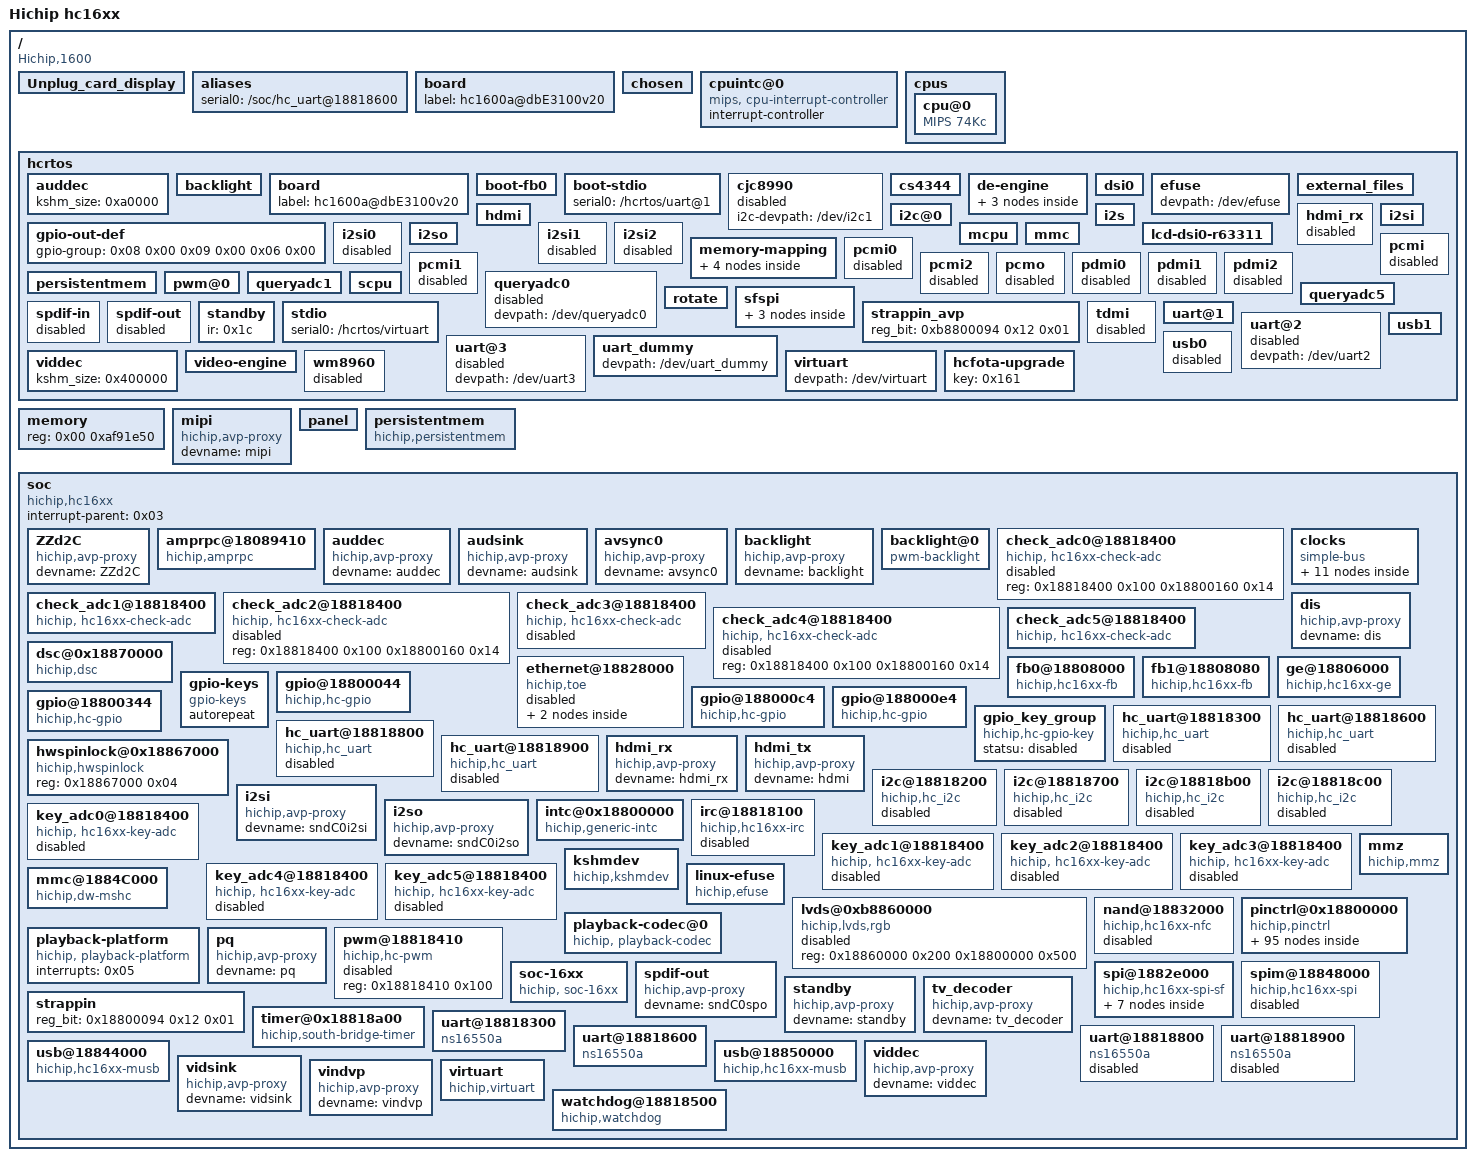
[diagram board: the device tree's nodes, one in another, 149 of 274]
/* r36sx-v26.dts — /hcrtos/ del NOR-DTB de FÁBRICA (fix-forward D-2b) */
#define CONFIG_MEMORY_SIZE 0x10000000
#define CONFIG_LINUX_MEMORY_SIZE 0xAF91E50
#define CONFIG_LINUX_MEMORY_OFFSET 0x0
#define CONFIG_FRAMEBUFFER_STATIC_PHYS (CONFIG_LINUX_MEMORY_OFFSET + CONFIG_LINUX_MEMORY_SIZE)
#define HCRTOS_SYSMEM_SIZE 0xB53600
#define HCRTOS_SYSMEM_OFFSET 0xBDA2E50
#define HCRTOS_BOOTMEM_SIZE 0x2000000
#define HCRTOS_BOOTMEM_OFFSET (((HCRTOS_SYSMEM_OFFSET < 0xc000000 ? HCRTOS_SYSMEM_OFFSET : 0xc000000) - HCRTOS_BOOTMEM_SIZE) & 0xffff0000)

/dts-v1/;

/ {
	#address-cells = <0x01>;
	#size-cells = <0x01>;
	compatible = "Hichip,1600";
	interrupt-parent = <0x01>;
	model = "Hichip hc16xx";

	Unplug_card_display {
		status = "okay";
	};

	aliases {
		serial0 = "/soc/hc_uart@18818600";
	};

	board {
		label = "hc1600a@dbE3100v20";
	};

	chosen {
		bootargs = "root=/dev/ram0 rootfstype=ramfs rw init=/linuxrc console=tty1 earlycon= no_console_suspend noirqdebug";
		stdout-path = "serial0:115200n8";
	};

	cpuintc@0 {
		#address-cells = <0x00>;
		#interrupt-cells = <0x01>;
		compatible = "mips, cpu-interrupt-controller";
		interrupt-controller;
		linux,phandle = <0x01>;
		phandle = <0x01>;
	};

	cpus {
		#address-cells = <0x01>;
		#size-cells = <0x00>;

		cpu@0 {
			clock = <0x05>;
			clocks = <0x02>;
			compatible = "MIPS 74Kc";
			device_type = "cpu";
			mcpu-dig-pll-clk = <0x384>;
			reg = <0x00>;
		};
	};

	hcrtos {
		#address-cells = <0x01>;
		#size-cells = <0x01>;

		auddec {
			kshm_size = <0xa0000>;
		};

		backlight {
			backlight-frequency = <0x186a0>;
			backlight-pwmdev = "/dev/pwm0";
			default-brightness-level = <0x99>;
			default-off;
			scale = <0xff>;
			status = "okay";
		};

		board {
			label = "hc1600a@dbE3100v20";
		};

		boot-fb0 {
			bits_per_pixel = <0x20>;
			buffer-header-size = <0x1000>;
			buffer-phy-static = <0xaf91e50 0xe11000>;
			buffer-source = "static";
			extra-buffer-size = <0x00>;
			reg = <0x1883a000 0x1000>;
			scale = <0x280 0x1e0 0x280 0x1e0>;
			status = "okay";
			use-static-header;
			xoffset = <0x00>;
			xres = <0x280>;
			xres_virtual = <0x280>;
			yoffset = <0x00>;
			yres = <0x1e0>;
			yres_virtual = <0x1e0>;
		};

		boot-stdio {
			serial0 = "/hcrtos/uart@1";
		};

		cjc8990 {
			i2c-devpath = "/dev/i2c1";
			status = "disabled";
		};

		cs4344 {
			status = "okay";
		};

		de-engine {
			cvbs-output = <0x00>;
			de-dig-pll-clk = <0x190>;
			de4k-clock = <0x06>;
			de4k-output = <0x01>;
			dual-output = <0x00>;
			mm-vc-fb-size = <0x19e000>;
			pinmux-vga-hsync = <0x0c 0x06>;
			pinmux-vga-vsync = <0x0d 0x06>;
			status = "okay";
			tvtype = <0x0f>;
			vga-output = <0x00>;
			vga-rgb-dac-b = <0x01>;
			vga-rgb-dac-g = <0x02>;
			vga-rgb-dac-r = <0x04>;

			VPInitInfo {

				rgb-cfg {
					b-rgb-enable = <0x01>;
					lcd-width = <0x280>;
					prgb-mode = <0x00>;
					rgb-mode = <0x00>;

					timing-para {
						active-polarity = <0x01>;
						b-enable = <0x01>;
						dpll-clock-reg-value = <0x00>;
						frame-rate = <0xea60>;
						h-active-len = <0x280>;
						h-back-len = <0x28>;
						h-display_len = <0x00>;
						h-front-len = <0xa8>;
						h-sync-len = <0x14>;
						h-sync-level = <0x00>;
						h-total-len = <0x364>;
						output-clock = <0x01>;
						v-active-len = <0x1e0>;
						v-back-len = <0x0c>;
						v-display_len = <0x00>;
						v-front-len = <0x16>;
						v-sync-len = <0x04>;
						v-sync-level = <0x00>;
						v-total-len = <0x206>;
					};
				};
			};
		};

		dsi0 {
			clock-frequency = <0x00>;
			dsi,cfg = <0x1c>;
			dsi,flags = <0x3fd>;
			dsi,format = <0x05>;
			dsi,lanes = <0x04>;
			dsi,swap = <0x00>;
			enable-delay-ms = <0x0a>;
			h-sync-level = <0x00>;
			init-delay-ms = <0x14>;
			lcd-reset-gpios-rtos = <0x06 0x01>;
			mipi-drive-strength = <0x02>;
			panel-init-sequence = <0x15c80211 0x156402 0x2900ff00 0x00 0x00 0x00 0x00 0x00 0x00 0x00 0x00 0x00 0x00 0x00 0x00 0x00 0x00 0x00 0x00 0x00 0x00 0x00 0x00 0x00 0x00 0x00 0x00 0x00 0x00 0x00 0x00 0x00 0x00 0x00 0x00 0x00 0x00 0x00 0x00 0x00 0x00 0x00 0x00 0x00 0x00 0x00 0x00 0x00 0x00 0x00 0x00 0x00 0x00 0x00 0x00 0x00 0x00 0x00 0x00 0x00 0x00 0x00 0x00 0x00 0x00 0x00 0x00 0x00 0x00 0x00 0x00 0x00 0x00 0x00 0x00 0x00 0x00 0x00 0x00 0x00 0x00 0x00 0x00 0x00 0x00 0x00 0x00 0x00 0x00 0x00 0x00 0x00 0x00 0x00 0x00 0x00 0x00 0x00 0x00 0x00 0x00 0x00 0x00 0x00 0x00 0x00 0x00 0x00 0x00 0x00 0x00 0x00 0x00 0x00 0x00 0x00 0x00 0x00 0x00 0x00 0x00 0x00 0x00 0x00 0x00 0x00 0x00 0x00 0x00 0x00 0x00 0x00 0x00 0x00 0x00 0x00 0x00 0x00 0x00 0x00 0x00 0x00 0x00 0x00 0x00 0x00 0x00 0x00 0x00 0x00 0x00 0x00 0x00 0x00 0x00 0x00 0x00 0x00 0x00 0x00 0x00 0x00 0x00 0x00 0x00 0x00 0x00 0x00 0x00 0x00 0x00 0x00 0x00 0x00 0x00 0x00 0x00 0x00 0x00 0x00 0x00 0x00 0x00 0x00 0x00 0x00 0x00 0x00 0x00 0x00 0x00 0x00 0x00 0x00 0x00 0x00 0x00 0x00 0x00 0x00 0x00 0x00 0x00 0x00 0x00 0x00 0x00 0x00 0x00 0x00 0x00 0x00 0x00 0x00 0x00 0x00 0x00 0x00 0x00 0x00 0x00 0x00 0x00 0x00 0x00 0x00 0x00 0x00 0x00 0x00 0x00 0x00 0x00 0x00 0x00 0x00 0x00 0x00 0x00 0x00 0x00 0x00 0x00 0x00 0x00 0x00 0x00 0x00 0x00 0x00 0x00 0x00 0x00 0x00 0x00 0x00 0x00 0x00 0x00 0x00 0x00 0x00 0x00 0x00 0x00 0x00 0x00 0x00 0x00 0x00 0x00 0x00 0x00 0x00 0x00 0x00 0x00 0x00 0x00 0x00 0x00 0x00 0x00 0x00 0x00 0x00 0x00 0x00 0x00 0x00 0x00 0x00 0x00 0x00 0x00 0x00 0x00 0x00 0x00 0x00 0x00 0x00 0x00 0x00 0x00 0x00 0x00 0x00 0x00 0x00 0x00 0x00 0x00 0x00 0x00 0x00 0x00 0x00 0x00 0x00 0x00 0x00 0x00 0x00 0x00 0x00 0x00 0x00 0x00 0x00 0x00 0x00 0x00 0x00 0x00 0x00 0x00 0x00 0x00 0x00 0x00 0x00 0x00 0x00 0x00 0x00 0x00 0x00 0x00 0x00 0x00 0x00 0x00 0x00 0x00 0x00 0x00 0x00 0x00 0x00 0x00 0x00 0x00 0x00 0x00 0x00 0x00 0x00 0x00 0x00 0x00 0x00 0x00 0x00 0x00 0x00 0x00 0x00 0x00 0x00 0x00 0x00 0x00 0x00 0x00 0x00 0x00 0x00 0x00 0x00 0x00 0x00 0x00 0x00 0x00 0x00 0x00 0x00 0x00 0x00 0x00 0x00 0x00 0x00 0x00 0x00 0x00 0x00 0x00 0x00 0x00 0x00 0x00 0x00 0x00 0x00 0x00 0x00 0x00 0x00 0x00 0x00 0x00 0x00 0x00 0x00 0x00 0x00 0x00 0x00 0x00 0x00 0x00 0x00 0x00 0x00 0x00 0x00 0x00 0x00 0x00 0x00 0x00 0x00 0x00 0x00 0x00 0x00 0x00 0x00 0x00 0x00 0x00 0x00 0x00 0x00 0x00 0x00 0x00 0x00 0x00 0x00 0x00 0x00 0x00 0x00 0x00 0x00 0x00 0x00 0x00 0x00 0x00 0x00 0x00 0x00 0x00 0x00 0x00 0x00 0x00 0x00 0x00 0x00 0x00 0x00 0x00 0x00 0x00 0x00 0x00 0x00 0x00 0x00 0x00 0x00 0x00 0x00 0x00 0x00 0x00 0x00 0x00 0x00 0x00 0x00 0x00 0x00 0x00 0x00 0x00 0x00 0x00 0x00 0x00 0x00 0x00 0x00 0x00 0x00 0x00 0x00 0x00 0x00 0x00 0x00 0x00 0x00 0x00 0x00 0x00 0x00 0x00 0x00 0x00 0x00 0x00 0x00 0x00 0x00 0x00 0x00 0x00 0x00 0x00 0x00 0x00 0x00 0x00 0x00 0x00 0x00 0x00 0x00 0x00 0x00 0x00 0x00 0x00 0x00 0x00 0x00 0x00 0x00 0x00 0x00 0x00 0x00 0x00 0x00 0x00 0x00 0x00 0x00 0x00 0x00 0x00 0x00 0x00 0x00 0x00 0x00 0x00 0x00 0x00 0x00 0x00 0x00 0x00 0x00 0x00 0x00 0x00 0x00 0x00 0x00 0x00 0x00 0x00 0x00 0x00 0x00 0x00 0x00 0x00 0x00 0x00 0x00 0x00 0x00 0x00 0x00 0x00 0x00 0x00 0x00 0x00 0x00 0x00 0x00 0x00 0x00 0x00 0x00 0x00 0x00 0x00 0x00 0x00 0x00 0x00 0x00 0x00 0x00 0x00 0x00 0x00 0x00 0x00 0x00 0x00 0x00 0x00 0x00 0x00 0x00 0x00 0x00 0x00 0x00 0x00 0x00 0x00 0x00 0x00 0x00 0x00 0x00 0x00 0x00 0x00 0x00 0x00 0x00 0x00 0x00 0x00 0x00 0x00 0x00 0x00 0x00 0x00 0x00 0x00 0x00 0x00 0x00 0x00 0x00 0x00 0x00 0x00 0x00 0x00 0x00 0x00 0x00 0x00 0x00 0x00 0x00 0x00 0x00 0x00 0x00 0x00 0x00 0x00 0x00>;
			prepare-delay-ms = <0x0a>;
			reg = <0x1884a000 0x300 0x18800444 0x08 0x18800080 0x08>;
			reset-delay-ms = <0x78>;
			src-sel = <0x01>;
			status = "okay";
			v-sync-level = <0x00>;
		};

		efuse {
			devpath = "/dev/efuse";
			status = "okay";
		};

		external_files {
			part-num = <0x04>;
			part1-filename = "dtb.bin";
			part1-label = "dtb";
			part2-filename = "avp.uImage";
			part2-label = "avp";
			part3-filename = "vmlinux.uImage";
			part3-label = "linux";
			part4-filename = "xgame-logo.bmp";
			part4-label = "logo";
			path-prefix = "boot";
		};

		gpio-out-def {
			gpio-group = <0x08 0x00 0x09 0x00 0x06 0x00>;
			status = "okay";
		};

		hdmi {
			default-off = <0x01>;
			i2c-devpath = "/dev/i2c0";
			pinmux-hotplug = <0x10 0x01>;
			status = "okay";
			tx_source = <0x01>;
		};

		hdmi_rx {
			pinmux-detect = <0x74 0x03>;
			pinmux-hotplugin = <0x74 0x00>;
			pinmux-i2c = <0x76 0x08 0x77 0x08>;
			status = "disabled";
		};

		i2c@0 {
			baudrate = <0x1c200>;
			devpath = "/dev/i2c0";
			mode = "master";
			pinmux-active = <0x11 0x01 0x12 0x01>;
			status = "okay";
		};

		i2s {
			ejtag = "disabled";
			format = "lj";
			pinmux-clock = <0x03 0x02 0x04 0x02>;
			status = "okay";
		};

		i2si {
			pinmux-data = <0x01 0x02>;
			status = "okay";
			volume = <0xff>;
		};

		i2si0 {
			status = "disabled";
		};

		i2si1 {
			status = "disabled";
		};

		i2si2 {
			status = "disabled";
		};

		i2so {
			mute-polar = <0x00>;
			pinmux-data = <0x05 0x02>;
			speed_fade = <0x05>;
			status = "okay";
			volume = <0xff>;
		};

		lcd-dsi0-r63311 {
			status = "okay";
		};

		mcpu {
			clock = <0x05>;
			mcpu-dig-pll-clk = <0x4b0>;
		};

		memory-mapping {
			#address-cells = <0x01>;
			#size-cells = <0x01>;

			bootmem {
				reg = <0x9da0000 0x2000000>;
			};

			mmz0 {
				blocklog = <0x0c>;
				id = <0x00>;
				reg = <0xcda2e50 0x325d1b0>;
			};

			mmz1 {
				blocklog = <0x0c>;
				id = <0x01>;
				mmzname = "kshm";
				reg = <0xc8f6450 0x4aca00>;
			};

			sysmem {
				reg = <0xbda2e50 0xb53600>;
			};
		};

		mmc {
			broken-cd;
			bus-width = <0x04>;
			cap-sd-highspeed;
			card-detect-delay = <0xc8>;
			clock-freq-min-max = <0x186a0 0x1312d00>;
			clock-frequency = <0xbcd3d80>;
			hcrtos-compatible = "hichip,dw-mshc";
			interrupts = <0x0a>;
			pinmux-active = <0x60 0xf9 0x61 0xf9 0x62 0xf9 0x63 0xf9 0x64 0xf9 0x65 0xf9>;
			reg = <0x1884c000 0x2000>;
			sd-uhs-sdr12;
			sd-uhs-sdr25;
			status = "okay";
		};

		pcmi {
			status = "disabled";
		};

		pcmi0 {
			status = "disabled";
		};

		pcmi1 {
			status = "disabled";
		};

		pcmi2 {
			status = "disabled";
		};

		pcmo {
			status = "disabled";
		};

		pdmi0 {
			status = "disabled";
		};

		pdmi1 {
			status = "disabled";
		};

		pdmi2 {
			status = "disabled";
		};

		persistentmem {
			mtdname = "persistentmem";
			size = <0x8000>;
			status = "okay";
		};

		pwm@0 {
			devpath = "/dev/pwm0";
			pinmux-active = <0x00 0x04>;
			status = "okay";
		};

		queryadc0 {
			devpath = "/dev/queryadc0";
			status = "disabled";
		};

		queryadc1 {
			adjust_channel = <0x00>;
			devpath = "/dev/queryadc1";
			status = "okay";
		};

		queryadc5 {
			adjust_channel = <0x00>;
			devpath = "/dev/queryadc5";
			status = "okay";
		};

		rotate {
			flip_support = <0x01>;
			h_flip = <0x00>;
			rotate = <0x00>;
			status = "okay";
			v_flip = <0x00>;
		};

		scpu {
			clock = <0x07>;
			scpu-dig-pll-clk = <0x320>;
		};

		sfspi {
			dma-mode = <0x01>;
			pinmux-active = <0x6f 0x01 0x70 0x01 0x71 0x01 0x72 0x01>;
			sclk = <0x2faf080>;
			status = "okay";

			spi_nor_flash {
				reg = <0x00>;
				spi-rx-bus-width = <0x01>;
				spi-tx-bus-width = <0x01>;
				status = "okay";

				partitions {
					part-num = <0x03>;
					part1-filename = "bootloader.bin";
					part1-label = "boot";
					part1-reg = <0x00 0x6c000>;
					part2-filename = "romfs.img";
					part2-label = "eromfs";
					part2-reg = <0x6c000 0x4000>;
					part3-filename = "persistentmem.bin";
					part3-label = "persistentmem";
					part3-reg = <0x70000 0x10000>;
				};
			};

			spidev@0 {
				devpath = "/dev/spidev0";
				reg = <0x00>;
				spi-max-frequency = <0x2faf080>;
				status = "okay";
			};
		};

		spdif-in {
			status = "disabled";
		};

		spdif-out {
			status = "disabled";
		};

		standby {
			ir = <0x1c>;
		};

		stdio {
			serial0 = "/hcrtos/virtuart";
		};

		strappin_avp {
			device_type = "hichip,hcrtos-setup-setbit";
			reg_bit = <0xb8800094 0x12 0x01>;
		};

		tdmi {
			status = "disabled";
		};

		uart@1 {
			devpath = "/dev/uart1";
			pinmux-active = <0x6e 0x02 0x73 0x02>;
			status = "okay";
		};

		uart@2 {
			devpath = "/dev/uart2";
			status = "disabled";
		};

		uart@3 {
			devpath = "/dev/uart3";
			status = "disabled";
		};

		uart_dummy {
			devpath = "/dev/uart_dummy";
			status = "okay";
		};

		usb0 {
			ctrl_base = <0x18800000>;
			dr_mode = "host";
			index_num = <0x00>;
			interrupt-names = "mc\0dma";
			interrupts = <0x35 0x34>;
			reg = <0x18844000 0x1000>;
			status = "disabled";
		};

		usb1 {
			ctrl_base = <0x18800000>;
			dr_mode = "host";
			index_num = <0x01>;
			interrupt-names = "mc\0dma";
			interrupts = <0x33 0x32>;
			reg = <0x18850000 0x1000>;
			status = "okay";
		};

		viddec {
			kshm_size = <0x400000>;
		};

		video-engine {
			avc-cmd-queue-size = <0x10000>;
			avc-extra-fb-num = <0x03>;
			avc-mb-nei-size = <0xf000>;
			avc-mem-size = <0x31fc000>;
			avc-vbv-size = <0x00>;
			clock = <0x05>;
			dynamic-resolution-support = <0x00>;
			mm-fb-size = <0x10cf200>;
			mm-mf-size = <0x198c00>;
			mm-vbv-size = <0x00>;
			mm-vin-fb-size = <0xff0000>;
			status = "okay";
			ve-dig-pll-clk = <0x1f4>;
			video-in-support = <0x00>;
		};

		virtuart {
			devpath = "/dev/virtuart";
			status = "okay";
		};

		wm8960 {
			status = "disabled";
		};
		hcfota-upgrade {
			status = "okay";
			key = <0x161>;
		};
	};

	memory {
		device_type = "memory";
		reg = <0x00 0xaf91e50>;
	};

	mipi {
		compatible = "hichip,avp-proxy";
		devname = "mipi";
	};

	panel {
		adc-bat-charging = "/dev/check_adc5";
		adc-bat-level = "/dev/check_adc1";
		backlight-delay = <0xc8>;
		boot-adc-bat-charging = "/dev/queryadc5";
		boot-adc-bat-level = "/dev/queryadc1";
		headphone-detect = <0x0f>;
		key-clk = <0x08>;
		key-do = <0x09>;
		key-fn = <0x02>;
		key-shoulder-left = <0x0b>;
		key-shoulder-right = <0x07>;
		key-tl1 = <0x0b>;
		key-tr1 = <0x07>;
		key-volume-down = <0x0c>;
		key-volume-up = <0x0d>;
		lcd-reset-pin = <0x06>;
		lcd-type = <0x04>;
		power-button = <0x0e>;
		power-pin = <0x01>;
		sdio-det = <0x6d>;
		speaker-output = <0x13>;
		status = "okay";
	};

	persistentmem {
		compatible = "hichip,persistentmem";
		mtdname = "persistentmem";
		size = <0x8000>;
	};

	soc {
		#address-cells = <0x01>;
		#size-cells = <0x01>;
		compatible = "hichip,hc16xx\0simple-bus";
		device_type = "soc";
		interrupt-parent = <0x03>;
		ranges;

		ZZd2C {
			compatible = "hichip,avp-proxy";
			devname = "ZZd2C";
		};

		amprpc@18089410 {
			compatible = "hichip,amprpc";
			interrupts = <0x42>;
			reg = <0x18800800 0x20 0x18800820 0x20 0x18800840 0x20 0x18800860 0x20 0x18800880 0x20 0x188008a0 0x20 0x188008c0 0x20 0x188008e0 0x20 0x18866800 0x20 0x18866820 0x20 0x18866840 0x20 0x18866860 0x20 0x18866880 0x20 0x188668a0 0x20 0x188668c0 0x20 0x188668e0 0x20>;
		};

		auddec {
			compatible = "hichip,avp-proxy";
			devname = "auddec";
		};

		audsink {
			compatible = "hichip,avp-proxy";
			devname = "audsink";
		};

		avsync0 {
			compatible = "hichip,avp-proxy";
			devname = "avsync0";
		};

		backlight {
			compatible = "hichip,avp-proxy";
			devname = "backlight";
		};

		backlight@0 {
			compatible = "pwm-backlight";
		};

		check_adc0@18818400 {
			compatible = "hichip, hc16xx-check-adc";
			reg = <0x18818400 0x100 0x18800160 0x14>;
			status = "disabled";
		};

		check_adc1@18818400 {
			adjust_channel = <0x00>;
			compatible = "hichip, hc16xx-check-adc";
			reg = <0x18818400 0x100 0x18800160 0x14>;
			status = "okay";
		};

		check_adc2@18818400 {
			compatible = "hichip, hc16xx-check-adc";
			reg = <0x18818400 0x100 0x18800160 0x14>;
			status = "disabled";
		};

		check_adc3@18818400 {
			adjust_channel = <0x01>;
			compatible = "hichip, hc16xx-check-adc";
			reg = <0x18818400 0x100 0x18800160 0x14>;
			status = "disabled";
		};

		check_adc4@18818400 {
			compatible = "hichip, hc16xx-check-adc";
			reg = <0x18818400 0x100 0x18800160 0x14>;
			status = "disabled";
		};

		check_adc5@18818400 {
			adjust_channel = <0x00>;
			compatible = "hichip, hc16xx-check-adc";
			reg = <0x18818400 0x100 0x18800160 0x14>;
			status = "okay";
		};

		clocks {
			#address-cells = <0x01>;
			#size-cells = <0x01>;
			compatible = "simple-bus";
			ranges;

			base_clk {
				#address-cells = <0x01>;
				#size-cells = <0x01>;
				compatible = "hichip,base-clk";
				ranges;

				cpu_clk@18800070 {
					#clock-cells = <0x00>;
					clock-output-names = "cpu_clk";
					clocks = <0x04 0x05 0x06 0x07 0x08 0x09 0x0a 0x0b>;
					compatible = "hichip,cpu-clk";
					ctrl_shift = [08];
					info_shift = [08];
					linux,phandle = <0x02>;
					phandle = <0x02>;
					reg = <0x18800074 0x04 0x18800070 0x04>;
					trig_shift = [16];
					width = [03];
				};
			};

			f1188 {
				#clock-cells = <0x00>;
				clock-frequency = <0x46cf7100>;
				clock-output-names = "f1188";
				compatible = "fixed-clock";
				linux,phandle = <0x09>;
				phandle = <0x09>;
			};

			f198 {
				#clock-cells = <0x00>;
				clock-frequency = <0xbcd3d80>;
				clock-output-names = "f198";
				compatible = "fixed-clock";
				linux,phandle = <0x07>;
				phandle = <0x07>;
			};

			f24 {
				#clock-cells = <0x00>;
				clock-frequency = <0x16e3600>;
				clock-output-names = "f24";
				compatible = "fixed-clock";
				linux,phandle = <0x0a>;
				phandle = <0x0a>;
			};

			f297 {
				#clock-cells = <0x00>;
				clock-frequency = <0x11b3dc40>;
				clock-output-names = "f297";
				compatible = "fixed-clock";
				linux,phandle = <0x06>;
				phandle = <0x06>;
			};

			f396 {
				#clock-cells = <0x00>;
				clock-frequency = <0x179a7b00>;
				clock-output-names = "f396";
				compatible = "fixed-clock";
				linux,phandle = <0x05>;
				phandle = <0x05>;
			};

			f594 {
				#clock-cells = <0x00>;
				clock-frequency = <0x2367b880>;
				clock-output-names = "f594";
				compatible = "fixed-clock";
				linux,phandle = <0x04>;
				phandle = <0x04>;
			};

			f900 {
				#clock-cells = <0x00>;
				clock-frequency = <0x35a4e900>;
				clock-output-names = "f900";
				compatible = "fixed-clock";
				linux,phandle = <0x08>;
				phandle = <0x08>;
			};

			fdig {
				#clock-cells = <0x00>;
				clock-frequency = <0x35a4e900>;
				clock-output-names = "fdig";
				compatible = "fixed-clock";
				linux,phandle = <0x0b>;
				phandle = <0x0b>;
			};

			mmcclk {
				#clock-cells = <0x00>;
				clock-frequency = <0xbcd3d80>;
				compatible = "fixed-clock";
				linux,phandle = <0x0e>;
				phandle = <0x0e>;
			};
		};

		dis {
			compatible = "hichip,avp-proxy";
			devname = "dis";
		};

		dsc@0x18870000 {
			compatible = "hichip,dsc";
			interrupts = <0x2c>;
			memory-cache-node = <0x00>;
			reg = <0x18834000 0x1000>;
			status = "okay";
		};

		ethernet@18828000 {
			compatible = "hichip,toe";
			device_type = "network";
			interrupts = <0x0e>;
			model = "HiChip TOE";
			phy-handle = <0x0c>;
			phy-mode = "rmii";
			phy-reversemii = <0x00>;
			reg = <0x18828000 0x2000 0x18800000 0x04>;
			rx-csum-enable = <0x01>;
			status = "disabled";
			tx-csum-enable = <0x01>;

			mdio {
				#address-cells = <0x01>;
				#size-cells = <0x00>;
				status = "okay";

				ethernet-phy@1 {
					device_type = "ethernet-phy";
					linux,phandle = <0x0c>;
					phandle = <0x0c>;
					reg = <0x01>;
				};
			};
		};

		fb0@18808000 {
			bits_per_pixel = <0x20>;
			buffer-header-size = <0x1000>;
			buffer-phy-static = <0xaf91e50 0xe11000>;
			buffer-source = "static";
			compatible = "hichip,hc16xx-fb";
			default-on;
			extra-buffer-size = <0x00>;
			reg = <0x1883a000 0x1000>;
			scale = <0x2d0 0x500 0x780 0x438>;
			status = "okay";
			use-static-header;
			xoffset = <0x00>;
			xres = <0x2d0>;
			xres_virtual = <0x2d0>;
			yoffset = <0x00>;
			yres = <0x500>;
			yres_virtual = <0x1400>;
		};

		fb1@18808080 {
			bits_per_pixel = <0x20>;
			buffer-source = "system";
			compatible = "hichip,hc16xx-fb";
			extra-buffer-size = <0x00>;
			pre-multiply = <0x00>;
			reg = <0x1883a080 0x1000>;
			scale = <0x280 0x1e0 0x280 0x1e0>;
			status = "okay";
			xoffset = <0x00>;
			xres = <0x280>;
			xres_virtual = <0x280>;
			yoffset = <0x00>;
			yres = <0x1e0>;
			yres_virtual = <0x1e0>;
		};

		ge@18806000 {
			cmdq_buf_size = <0x3c000>;
			compatible = "hichip,hc16xx-ge";
			interrupts = <0x04>;
			reg = <0x18806000 0x2000 0x18800000 0x1000>;
			status = "okay";
		};

		gpio-keys {
			#address-cells = <0x01>;
			#size-cells = <0x00>;
			autorepeat;
			compatible = "gpio-keys";
		};

		gpio@18800044 {
			#gpio-cells = <0x02>;
			#interrupt-cells = <0x01>;
			compatible = "hichip,hc-gpio";
			gpio-base = <0x00>;
			gpio-controller;
			gpio-ranges = <0x11 0x00 0x00 0x20>;
			interrupt-controller;
			interrupt-parent = <0x03>;
			interrupts = <0x00>;
			ngpio = <0x20>;
			reg = <0x18800044 0x1c>;
		};

		gpio@188000c4 {
			#gpio-cells = <0x02>;
			#interrupt-cells = <0x01>;
			compatible = "hichip,hc-gpio";
			gpio-base = <0x20>;
			gpio-controller;
			gpio-ranges = <0x11 0x00 0x20 0x20>;
			interrupt-controller;
			interrupt-parent = <0x03>;
			interrupts = <0x00>;
			ngpio = <0x20>;
			reg = <0x188000c4 0x1c>;
		};

		gpio@188000e4 {
			#gpio-cells = <0x02>;
			#interrupt-cells = <0x01>;
			compatible = "hichip,hc-gpio";
			gpio-base = <0x40>;
			gpio-controller;
			gpio-ranges = <0x11 0x00 0x40 0x20>;
			interrupt-controller;
			interrupt-parent = <0x03>;
			interrupts = <0x00>;
			ngpio = <0x20>;
			reg = <0x188000e4 0x1c>;
		};

		gpio@18800344 {
			#gpio-cells = <0x02>;
			#interrupt-cells = <0x01>;
			compatible = "hichip,hc-gpio";
			gpio-base = <0x60>;
			gpio-controller;
			gpio-ranges = <0x11 0x00 0x60 0x20>;
			interrupt-controller;
			interrupt-parent = <0x03>;
			interrupts = <0x00>;
			ngpio = <0x20>;
			reg = <0x18800344 0x1c>;
		};

		gpio_key_group {
			compatible = "hichip,hc-gpio-key";
			statsu = "disabled";
		};

		hc_uart@18818300 {
			compatible = "hichip,hc_uart";
			device_type = "hichip,platform-setup-setbit";
			interrupts = <0x10>;
			reg = <0x18818300 0x0c>;
			reg_bit = <0x18800060 0x11 0x00>;
			status = "disabled";
		};

		hc_uart@18818600 {
			compatible = "hichip,hc_uart";
			device_type = "hichip,platform-setup-setbit";
			interrupts = <0x11>;
			reg = <0x18818600 0x0c>;
			reg_bit = <0x18800060 0x11 0x00>;
			status = "disabled";
		};

		hc_uart@18818800 {
			compatible = "hichip,hc_uart";
			device_type = "hichip,platform-setup-setbit";
			interrupts = <0x36>;
			reg = <0x18818800 0x0c>;
			reg_bit = <0x18800064 0x0b 0x00>;
			status = "disabled";
		};

		hc_uart@18818900 {
			compatible = "hichip,hc_uart";
			device_type = "hichip,platform-setup-setbit";
			interrupts = <0x37>;
			reg = <0x18818900 0x0c>;
			reg_bit = <0x18800064 0x0b 0x00>;
			status = "disabled";
		};

		hdmi_rx {
			compatible = "hichip,avp-proxy";
			devname = "hdmi_rx";
		};

		hdmi_tx {
			compatible = "hichip,avp-proxy";
			devname = "hdmi";
		};

		hwspinlock@0x18867000 {
			compatible = "hichip,hwspinlock";
			reg = <0x18867000 0x04>;
		};

		i2c@18818200 {
			baud_speed = <0x186a0>;
			compatible = "hichip,hc_i2c";
			interrupts = <0x12>;
			master-mode = <0x01>;
			reg = <0x18818200 0x100>;
			status = "disabled";
		};

		i2c@18818700 {
			baud_speed = <0x186a0>;
			compatible = "hichip,hc_i2c";
			interrupts = <0x19>;
			master-mode = <0x01>;
			reg = <0x18818700 0x100>;
			status = "disabled";
		};

		i2c@18818b00 {
			baud_speed = <0x186a0>;
			compatible = "hichip,hc_i2c";
			interrupts = <0x1a>;
			master-mode = <0x01>;
			reg = <0x18818b00 0x100>;
			status = "disabled";
		};

		i2c@18818c00 {
			baud_speed = <0x186a0>;
			compatible = "hichip,hc_i2c";
			interrupts = <0x2b>;
			master-mode = <0x01>;
			reg = <0x18818c00 0x100>;
			status = "disabled";
		};

		i2si {
			compatible = "hichip,avp-proxy";
			devname = "sndC0i2si";
		};

		i2so {
			compatible = "hichip,avp-proxy";
			devname = "sndC0i2so";
		};

		intc@0x18800000 {
			#interrupt-cells = <0x01>;
			compatible = "hichip,generic-intc";
			interrupt-controller;
			interrupt-parent = <0x01>;
			interrupts = <0x03 0x02>;
			linux,phandle = <0x03>;
			max-irqs = <0x60>;
			phandle = <0x03>;
			reg = <0x18800028 0x18 0x18800030 0x18 0x18800038 0x18 0x18800020 0x18>;
		};

		irc@18818100 {
			compatible = "hichip,hc16xx-irc";
			interrupts = <0x13>;
			linux,rc-map-name = "rc-hcdemo";
			pinctrl-0 = <0x10>;
			pinctrl-names = "active";
			reg = <0x18818100 0x60>;
			status = "disabled";
		};

		key_adc0@18818400 {
			compatible = "hichip, hc16xx-key-adc";
			interrupts = <0x25>;
			reg = <0x18818400 0x100 0x18800160 0x14>;
			status = "disabled";
		};

		key_adc1@18818400 {
			compatible = "hichip, hc16xx-key-adc";
			interrupts = <0x25>;
			reg = <0x18818400 0x100 0x18800160 0x14>;
			status = "disabled";
		};

		key_adc2@18818400 {
			compatible = "hichip, hc16xx-key-adc";
			interrupts = <0x25>;
			reg = <0x18818400 0x100 0x18800160 0x14>;
			status = "disabled";
		};

		key_adc3@18818400 {
			adc_ref_voltage = <0x762>;
			compatible = "hichip, hc16xx-key-adc";
			interrupts = <0x25>;
			key-map = <0xc8 0x1f4 0x67 0x259 0x352 0x6c 0x353 0x44c 0x69 0x44d 0x514 0x6a 0x515 0x5dc 0x160 0x5dd 0x686 0x8b 0x687 0x6fe 0xae>;
			reg = <0x18818400 0x100 0x18800160 0x14>;
			status = "disabled";
		};

		key_adc4@18818400 {
			compatible = "hichip, hc16xx-key-adc";
			interrupts = <0x25>;
			reg = <0x18818400 0x100 0x18800160 0x14>;
			status = "disabled";
		};

		key_adc5@18818400 {
			compatible = "hichip, hc16xx-key-adc";
			interrupts = <0x25>;
			reg = <0x18818400 0x100 0x18800160 0x14>;
			status = "disabled";
		};

		kshmdev {
			compatible = "hichip,kshmdev";
		};

		linux-efuse {
			compatible = "hichip,efuse";
		};

		lvds@0xb8860000 {
			compatible = "hichip,lvds,rgb";
			reg = <0x18860000 0x200 0x18800000 0x500>;
			status = "disabled";
		};

		mmc@1884C000 {
			broken-cd;
			bus-width = <0x04>;
			cap-sd-highspeed;
			card-detect-delay = <0xc8>;
			clock-freq-min-max = <0x186a0 0x1312d00>;
			clock-names = "biu\0ciu";
			clocks = <0x0e 0x0e>;
			compatible = "hichip,dw-mshc";
			interrupts = <0x0a>;
			pinctrl-0 = <0x0f>;
			pinctrl-names = "default";
			reg = <0x1884c000 0x2000>;
			sd-uhs-sdr12;
			sd-uhs-sdr25;
			status = "okay";
		};

		mmz {
			compatible = "hichip,mmz";
		};

		nand@18832000 {
			compatible = "hichip,hc16xx-nfc";
			interrupts = <0x30>;
			nand-ecc-algo = "bch";
			nand-ecc-mode = "hw";
			nand-on-flash-bbt;
			reg = <0x18832000 0x60>;
			scrambling = <0x00>;
			status = "disabled";
		};

		pinctrl@0x18800000 {
			compatible = "hichip,pinctrl";
			linux,phandle = <0x11>;
			phandle = <0x11>;
			pins = "GPIO_L_00\0GPIO_L_01\0GPIO_L_02\0GPIO_L_03\0GPIO_L_04\0GPIO_L_05\0GPIO_L_06\0GPIO_L_07\0GPIO_L_08\0GPIO_L_09\0GPIO_L_10\0GPIO_L_11\0GPIO_L_12\0GPIO_L_13\0GPIO_L_14\0GPIO_L_15\0GPIO_L_16\0GPIO_L_17\0GPIO_L_18\0GPIO_L_19\0GPIO_L_20\0GPIO_L_21\0GPIO_L_22\0GPIO_L_23\0GPIO_L_24\0GPIO_L_25\0GPIO_L_26\0GPIO_L_27\0GPIO_L_28\0GPIO_L_29\0GPIO_L_30\0GPIO_L_31\0GPIO_B_00\0GPIO_B_01\0GPIO_B_02\0GPIO_B_03\0GPIO_B_04\0GPIO_B_05\0GPIO_B_06\0GPIO_B_07\0GPIO_B_08\0GPIO_B_09\0GPIO_B_10\0GPIO_B_11\0GPIO_B_12\0GPIO_B_13\0GPIO_B_14\0GPIO_B_15\0GPIO_B_16\0GPIO_B_17\0GPIO_B_18\0GPIO_B_19\0GPIO_B_20\0GPIO_B_21\0GPIO_B_22\0GPIO_B_23\0GPIO_B_24\0GPIO_B_25\0GPIO_B_26\0GPIO_B_27\0GPIO_B_28\0GPIO_B_29\0GPIO_B_30\0GPIO_B_31\0GPIO_R_00\0GPIO_R_01\0GPIO_R_02\0GPIO_R_03\0GPIO_R_04\0GPIO_R_05\0GPIO_R_06\0GPIO_R_07\0GPIO_R_08\0GPIO_R_09\0GPIO_R_10\0GPIO_R_11\0GPIO_R_12\0GPIO_R_13\0GPIO_R_14\0GPIO_R_15\0GPIO_R_16\0GPIO_R_17\0GPIO_R_18\0GPIO_R_19\0GPIO_R_20\0GPIO_R_21\0GPIO_R_22\0GPIO_R_23\0GPIO_R_24\0GPIO_R_25\0GPIO_R_26\0GPIO_R_27\0GPIO_R_28\0GPIO_R_29\0GPIO_R_30\0GPIO_R_31\0GPIO_T_00\0GPIO_T_01\0GPIO_T_02\0GPIO_T_03\0GPIO_T_04\0GPIO_T_05\0GPIO_T_06\0GPIO_T_07\0GPIO_T_08\0GPIO_T_09\0GPIO_T_10\0GPIO_T_11\0GPIO_T_12\0GPIO_T_13\0GPIO_T_14\0GPIO_T_15\0GPIO_T_16\0GPIO_T_17\0GPIO_T_18\0GPIO_T_19\0GPIO_T_20\0GPIO_T_21\0GPIO_T_22\0GPIO_T_23\0GPIO_T_24\0GPIO_T_25\0GPIO_T_26\0GPIO_T_27\0GPIO_T_28\0GPIO_T_29\0GPIO_T_30\0GPIO_T_31";
			reg = <0x18800000 0x820>;

			functions {

				pctl_i2c0 {
					field-value-0 = <0x05>;
					field-value-1 = <0x05>;
					groups = "GPIO_L_12\0GPIO_L_13";
				};

				pctl_irc {
					field-value-0 = <0x01>;
					groups = "GPIO_L_14";
					linux,phandle = <0x10>;
					phandle = <0x10>;
				};

				pctl_sdio {
					field-value-0 = <0xf9>;
					field-value-1 = <0xf9>;
					field-value-2 = <0xf9>;
					field-value-3 = <0xf9>;
					field-value-4 = <0xf9>;
					field-value-5 = <0xf9>;
					field-value-6 = <0xf9>;
					groups = "GPIO_T_00\0GPIO_T_01\0GPIO_T_02\0GPIO_T_03\0GPIO_T_04\0GPIO_T_05";
					linux,phandle = <0x0f>;
					phandle = <0x0f>;
				};

				pctl_sf {
					field-value-0 = <0x01>;
					field-value-1 = <0x01>;
					field-value-2 = <0x01>;
					field-value-3 = <0x01>;
					field-value-4 = <0x01>;
					field-value-5 = <0x01>;
					groups = "GPIO_T_14\0GPIO_T_15\0GPIO_T_16\0GPIO_T_17\0GPIO_T_18\0GPIO_T_19";
					linux,phandle = <0x0d>;
					phandle = <0x0d>;
				};

				pctl_spim {
					field-value-0 = <0x0a>;
					field-value-1 = <0x0a>;
					field-value-2 = <0x0a>;
					field-value-3 = <0x0a>;
					field-value-4 = <0x00>;
					groups = "GPIO_B_12\0GPIO_B_13\0GPIO_B_15\0GPIO_B_16\0GPIO_B_17";
				};
			};

			gpio-groups {
				#address-cells = <0x01>;
				#size-cells = <0x01>;

				GPIO_B@gpio-group2 {
					pins = <0x20 0x21 0x22 0x23 0x24 0x25 0x26 0x27 0x28 0x29 0x2a 0x2b 0x2c 0x2d 0x2e 0x2f 0x30 0x31 0x32 0x33 0x34 0x35 0x36 0x37 0x38 0x39 0x3a 0x3b 0x3c 0x3d 0x3e 0x3f>;
					reg = <0x188004e0 0x30>;
				};

				GPIO_L@gpio-group1 {
					pins = <0x00 0x01 0x02 0x03 0x04 0x05 0x06 0x07 0x08 0x09 0x0a 0x0b 0x0c 0x0d 0x0e 0x0f 0x10 0x11 0x12 0x13 0x14 0x15 0x16 0x17 0x18 0x19 0x1a 0x1b 0x1c 0x1d 0x1e 0x1f>;
					reg = <0x188004a0 0x30>;
				};

				GPIO_R@gpio-group3 {
					pins = <0x40 0x41 0x42 0x43 0x44 0x45 0x46 0x47 0x48 0x49 0x4a 0x4b 0x4c 0x4d 0x4e 0x4f 0x50 0x51 0x52 0x53 0x54 0x55 0x56 0x57 0x58 0x59 0x5a 0x5b 0x5c 0x5d 0x5e 0x5f>;
					reg = <0x18800520 0x30>;
				};

				GPIO_T@gpio-group4 {
					pins = <0x60 0x61 0x62 0x63 0x64 0x65 0x66 0x67 0x68 0x69 0x6a 0x6b 0x6c 0x6d 0x6e 0x6f 0x70 0x71 0x72 0x73 0x74 0x75 0x76 0x77 0x78 0x79 0x7a 0x7b 0x7c 0x7d 0x7e 0x7f>;
					reg = <0x18800560 0x30>;
				};
			};

			groups {

				GPIO_B_00 {
					pins = <0x20>;
					reg-offset = <0x4e0>;
				};

				GPIO_B_01 {
					pins = <0x21>;
					reg-offset = <0x4e1>;
				};

				GPIO_B_02 {
					pins = <0x22>;
					reg-offset = <0x4e2>;
				};

				GPIO_B_03 {
					pins = <0x23>;
					reg-offset = <0x4e3>;
				};

				GPIO_B_04 {
					pins = <0x24>;
					reg-offset = <0x4e4>;
				};

				GPIO_B_05 {
					pins = <0x25>;
					reg-offset = <0x4e5>;
				};

				GPIO_B_06 {
					pins = <0x26>;
					reg-offset = <0x4e6>;
				};

				GPIO_B_07 {
					pins = <0x27>;
					reg-offset = <0x4e7>;
				};

				GPIO_B_08 {
					pins = <0x28>;
					reg-offset = <0x4e8>;
				};

				GPIO_B_09 {
					pins = <0x29>;
					reg-offset = <0x4e9>;
				};

				GPIO_B_10 {
					pins = <0x2a>;
					reg-offset = <0x4ea>;
				};

				GPIO_B_11 {
					pins = <0x2b>;
					reg-offset = <0x4eb>;
				};

				GPIO_B_12 {
					pins = <0x2c>;
					reg-offset = <0x4ec>;
				};

				GPIO_B_13 {
					pins = <0x2d>;
					reg-offset = <0x4ed>;
				};

				GPIO_B_14 {
					pins = <0x2e>;
					reg-offset = <0x4ee>;
				};

				GPIO_B_15 {
					pins = <0x2f>;
					reg-offset = <0x4ef>;
				};

				GPIO_B_16 {
					pins = <0x30>;
					reg-offset = <0x4f0>;
				};

				GPIO_B_17 {
					pins = <0x31>;
					reg-offset = <0x4f1>;
				};

				GPIO_B_18 {
					pins = <0x32>;
					reg-offset = <0x4f2>;
				};

				GPIO_B_19 {
					pins = <0x33>;
					reg-offset = <0x4f3>;
				};

				GPIO_B_20 {
					pins = <0x34>;
					reg-offset = <0x4f4>;
				};

				GPIO_B_21 {
					pins = <0x35>;
					reg-offset = <0x4f5>;
				};

				GPIO_B_22 {
					pins = <0x36>;
					reg-offset = <0x4f6>;
				};

				GPIO_B_23 {
					pins = <0x37>;
					reg-offset = <0x4f7>;
				};

				GPIO_B_24 {
					pins = <0x38>;
					reg-offset = <0x4f8>;
				};

				GPIO_L_00 {
					pins = <0x00>;
					reg-offset = <0x4a0>;
				};

				GPIO_L_01 {
					pins = <0x01>;
					reg-offset = <0x4a1>;
				};

				GPIO_L_02 {
					pins = <0x02>;
					reg-offset = <0x4a2>;
				};

				GPIO_L_03 {
					pins = <0x03>;
					reg-offset = <0x4a3>;
				};

				GPIO_L_04 {
					pins = <0x04>;
					reg-offset = <0x4a4>;
				};

				GPIO_L_05 {
					pins = <0x05>;
					reg-offset = <0x4a5>;
				};

				GPIO_L_06 {
					pins = <0x06>;
					reg-offset = <0x4a6>;
				};

				GPIO_L_07 {
					pins = <0x07>;
					reg-offset = <0x4a7>;
				};

				GPIO_L_08 {
					pins = <0x08>;
					reg-offset = <0x4a8>;
				};

				GPIO_L_09 {
					pins = <0x09>;
					reg-offset = <0x4a9>;
				};

				GPIO_L_10 {
					pins = <0x0a>;
					reg-offset = <0x4aa>;
				};

				GPIO_L_11 {
					pins = <0x0b>;
					reg-offset = <0x4ab>;
				};

				GPIO_L_12 {
					pins = <0x0c>;
					reg-offset = <0x4ac>;
				};

				GPIO_L_13 {
					pins = <0x0d>;
					reg-offset = <0x4ad>;
				};

				GPIO_L_14 {
					pins = <0x0e>;
					reg-offset = <0x4ae>;
				};

				GPIO_L_15 {
					pins = <0x0f>;
					reg-offset = <0x4af>;
				};

				GPIO_L_16 {
					pins = <0x10>;
					reg-offset = <0x4b0>;
				};

				GPIO_L_17 {
					pins = <0x11>;
					reg-offset = <0x4b1>;
				};

				GPIO_L_18 {
					pins = <0x12>;
					reg-offset = <0x4b2>;
				};

				GPIO_L_19 {
					pins = <0x13>;
					reg-offset = <0x4b3>;
				};

				GPIO_L_20 {
					pins = <0x14>;
					reg-offset = <0x4b4>;
				};

				GPIO_R_00 {
					pins = <0x40>;
					reg-offset = <0x520>;
				};

				GPIO_R_01 {
					pins = <0x41>;
					reg-offset = <0x521>;
				};

				GPIO_R_02 {
					pins = <0x42>;
					reg-offset = <0x522>;
				};

				GPIO_R_03 {
					pins = <0x43>;
					reg-offset = <0x523>;
				};

				GPIO_R_04 {
					pins = <0x44>;
					reg-offset = <0x524>;
				};

				GPIO_R_05 {
					pins = <0x45>;
					reg-offset = <0x525>;
				};

				GPIO_R_06 {
					pins = <0x46>;
					reg-offset = <0x526>;
				};

				GPIO_R_07 {
					pins = <0x47>;
					reg-offset = <0x527>;
				};

				GPIO_R_08 {
					pins = <0x48>;
					reg-offset = <0x528>;
				};

				GPIO_R_09 {
					pins = <0x49>;
					reg-offset = <0x529>;
				};

				GPIO_R_10 {
					pins = <0x4a>;
					reg-offset = <0x52a>;
				};

				GPIO_T_00 {
					pins = <0x60>;
					reg-offset = <0x560>;
				};

				GPIO_T_01 {
					pins = <0x61>;
					reg-offset = <0x561>;
				};

				GPIO_T_02 {
					pins = <0x62>;
					reg-offset = <0x562>;
				};

				GPIO_T_03 {
					pins = <0x63>;
					reg-offset = <0x563>;
				};

				GPIO_T_04 {
					pins = <0x64>;
					reg-offset = <0x564>;
				};

				GPIO_T_05 {
					pins = <0x65>;
					reg-offset = <0x565>;
				};

				GPIO_T_06 {
					pins = <0x66>;
					reg-offset = <0x566>;
				};

				GPIO_T_07 {
					pins = <0x67>;
					reg-offset = <0x567>;
				};

				GPIO_T_08 {
					pins = <0x68>;
					reg-offset = <0x568>;
				};

				GPIO_T_09 {
					pins = <0x69>;
					reg-offset = <0x569>;
				};

				GPIO_T_10 {
					pins = <0x6a>;
					reg-offset = <0x56a>;
				};

				GPIO_T_11 {
					pins = <0x6b>;
					reg-offset = <0x56b>;
				};

				GPIO_T_12 {
					pins = <0x6c>;
					reg-offset = <0x56c>;
				};

				GPIO_T_13 {
					pins = <0x6d>;
					reg-offset = <0x56d>;
				};

				GPIO_T_14 {
					pins = <0x6e>;
					reg-offset = <0x56e>;
				};

				GPIO_T_15 {
					pins = <0x6f>;
					reg-offset = <0x56f>;
				};

				GPIO_T_16 {
					pins = <0x70>;
					reg-offset = <0x570>;
				};

				GPIO_T_17 {
					pins = <0x71>;
					reg-offset = <0x571>;
				};

				GPIO_T_18 {
					pins = <0x72>;
					reg-offset = <0x572>;
				};

				GPIO_T_19 {
					pins = <0x73>;
					reg-offset = <0x573>;
				};

				GPIO_T_20 {
					pins = <0x74>;
					reg-offset = <0x574>;
				};

				GPIO_T_21 {
					pins = <0x75>;
					reg-offset = <0x575>;
				};

				GPIO_T_22 {
					pins = <0x76>;
					reg-offset = <0x576>;
				};

				GPIO_T_23 {
					pins = <0x77>;
					reg-offset = <0x577>;
				};

				GPIO_T_24 {
					pins = <0x78>;
					reg-offset = <0x578>;
				};

				GPIO_T_25 {
					pins = <0x79>;
					reg-offset = <0x579>;
				};
			};
		};

		playback-codec@0 {
			compatible = "hichip, playback-codec";
		};

		playback-platform {
			compatible = "hichip, playback-platform";
			interrupts = <0x05>;
		};

		pq {
			compatible = "hichip,avp-proxy";
			devname = "pq";
		};

		pwm@18818410 {
			compatible = "hichip,hc-pwm";
			reg = <0x18818410 0x100>;
			status = "disabled";
		};

		soc-16xx {
			compatible = "hichip, soc-16xx";
		};

		spdif-out {
			compatible = "hichip,avp-proxy";
			devname = "sndC0spo";
		};

		spi@1882e000 {
			#address-cells = <0x01>;
			#size-cells = <0x00>;
			compatible = "hichip,hc16xx-spi-sf";
			dma-mode = <0x01>;
			interrupts = <0x23>;
			num-cs = <0x02>;
			pinctrl-0 = <0x0d>;
			pinctrl-names = "active";
			reg = <0x1882e000 0xe0 0x1f000000 0x1000 0x1f000000 0x1000>;
			sclk = <0x2faf080>;

			spi_flash@0 {
				#address-cells = <0x01>;
				#size-cells = <0x01>;
				compatible = "m25p80";
				reg = <0x00>;
				spi-max-frequency = <0x5f5e100>;
				spi-rx-bus-width = <0x02>;
				spi-tx-bus-width = <0x02>;

				partitions {
					#address-cells = <0x01>;
					#size-cells = <0x01>;
					compatible = "fixed-partitions";

					boot {
						label = "boot";
						reg = <0x00 0x6c000>;
					};

					eromfs {
						label = "eromfs";
						reg = <0x6c000 0x4000>;
					};

					nor {
						label = "nor";
						reg = <0x00 0x80000>;
					};

					persistentmem {
						label = "persistentmem";
						reg = <0x70000 0x10000>;
					};
				};
			};

			spidev@0 {
				compatible = "rohm,dh2228fv";
				reg = <0x01>;
				spi-max-frequency = <0x5f5e100>;
			};
		};

		spim@18848000 {
			clk_ratio = <0x04>;
			compatible = "hichip,hc16xx-spi";
			cs-pin = <0x31>;
			dma-mode = <0x01>;
			reg = <0x18848000 0x100>;
			status = "disabled";
			transfer-mode = <0x00>;
		};

		standby {
			compatible = "hichip,avp-proxy";
			devname = "standby";
		};

		strappin {
			device_type = "hichip,platform-setup-setbit";
			reg_bit = <0x18800094 0x12 0x01>;
		};

		timer@0x18818a00 {
			clock-frequency = <0x16e3600>;
			compatible = "hichip,south-bridge-timer";
			interrupts = <0x16>;
			reg = <0x18818a00 0x100>;
		};

		tv_decoder {
			compatible = "hichip,avp-proxy";
			devname = "tv_decoder";
		};

		uart@18818300 {
			clock-frequency = <0x1c2000>;
			compatible = "ns16550a";
			current-speed = <0x1c200>;
			device_type = "hichip,platform-setup-setbit";
			fifo-size = <0x10>;
			interrupts = <0x10>;
			reg = <0x18818300 0x0c>;
			reg-io-width = <0x01>;
			reg-offset = <0x00>;
			reg-shift = <0x00>;
			reg_bit = <0x18800060 0x10 0x00 0x18800094 0x12 0x01>;
		};

		uart@18818600 {
			clock-frequency = <0x1c2000>;
			compatible = "ns16550a";
			current-speed = <0x1c200>;
			device_type = "hichip,platform-setup-setbit";
			fifo-size = <0x10>;
			interrupts = <0x11>;
			reg = <0x18818600 0x0c>;
			reg-io-width = <0x01>;
			reg-offset = <0x00>;
			reg-shift = <0x00>;
			reg_bit = <0x18800060 0x11 0x00>;
		};

		uart@18818800 {
			clock-frequency = <0x1c2000>;
			compatible = "ns16550a";
			current-speed = <0x1c200>;
			device_type = "hichip,platform-setup-setbit";
			fifo-size = <0x10>;
			interrupts = <0x36>;
			reg = <0x18818800 0x0c>;
			reg-io-width = <0x01>;
			reg-offset = <0x00>;
			reg-shift = <0x00>;
			reg_bit = <0x18800064 0x0b 0x00>;
			status = "disabled";
		};

		uart@18818900 {
			clock-frequency = <0x1c2000>;
			compatible = "ns16550a";
			current-speed = <0x1c200>;
			device_type = "hichip,platform-setup-setbit";
			fifo-size = <0x10>;
			interrupts = <0x37>;
			reg = <0x18818900 0x0c>;
			reg-io-width = <0x01>;
			reg-offset = <0x00>;
			reg-shift = <0x00>;
			reg_bit = <0x18800064 0x0b 0x00>;
			status = "disabled";
		};

		usb@18844000 {
			compatible = "hichip,hc16xx-musb";
			ctrl_base = <0x18800000>;
			dr_mode = "host";
			index_num = <0x00>;
			interrupt-names = "mc\0dma";
			interrupts = <0x35 0x34>;
			reg = <0x18844000 0x1000>;
			status = "okay";
		};

		usb@18850000 {
			compatible = "hichip,hc16xx-musb";
			ctrl_base = <0x18800000>;
			dr_mode = "host";
			index_num = <0x01>;
			interrupt-names = "mc\0dma";
			interrupts = <0x33 0x32>;
			reg = <0x18850000 0x1000>;
			status = "okay";
		};

		viddec {
			compatible = "hichip,avp-proxy";
			devname = "viddec";
		};

		vidsink {
			compatible = "hichip,avp-proxy";
			devname = "vidsink";
		};

		vindvp {
			compatible = "hichip,avp-proxy";
			devname = "vindvp";
		};

		virtuart {
			compatible = "hichip,virtuart";
		};

		watchdog@18818500 {
			compatible = "hichip,watchdog";
			interrupts = <0x17>;
			reg = <0x18818500 0x0a>;
			timeout-sec = <0x1e>;
		};
	};
};
